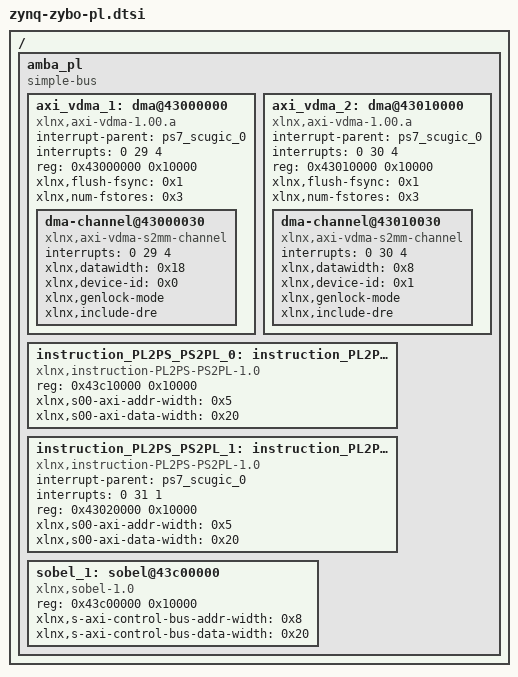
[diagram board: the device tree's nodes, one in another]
/*
 * CAUTION: This file is automatically generated by Xilinx.
 * Version: HSI 
 * Today is: Thu Jan 14 14:43:05 2016
*/


/  {
	amba_pl: amba_pl {
		#address-cells = <1>;
		#size-cells = <1>;
		compatible = "simple-bus";
		ranges ;
		axi_vdma_1: dma@43000000 {
			#dma-cells = <1>;
			compatible = "xlnx,axi-vdma-1.00.a";
			interrupt-parent = <&ps7_scugic_0>;
			interrupts = <0 29 4>;
			reg = <0x43000000 0x10000>;
			xlnx,flush-fsync = <0x1>;
			xlnx,num-fstores = <0x3>;
			dma-channel@43000030 {
				compatible = "xlnx,axi-vdma-s2mm-channel";
				interrupts = <0 29 4>;
				xlnx,datawidth = <0x18>;
				xlnx,device-id = <0x0>;
				xlnx,genlock-mode ;
				xlnx,include-dre ;
			};
		};
		axi_vdma_2: dma@43010000 {
			#dma-cells = <1>;
			compatible = "xlnx,axi-vdma-1.00.a";
			interrupt-parent = <&ps7_scugic_0>;
			interrupts = <0 30 4>;
			reg = <0x43010000 0x10000>;
			xlnx,flush-fsync = <0x1>;
			xlnx,num-fstores = <0x3>;
			dma-channel@43010030 {
				compatible = "xlnx,axi-vdma-s2mm-channel";
				interrupts = <0 30 4>;
				xlnx,datawidth = <0x8>;
				xlnx,device-id = <0x1>;
				xlnx,genlock-mode ;
				xlnx,include-dre ;
			};
		};
		instruction_PL2PS_PS2PL_0: instruction_PL2PS_PS2PL@43c10000 {
			compatible = "xlnx,instruction-PL2PS-PS2PL-1.0";
			reg = <0x43c10000 0x10000>;
			xlnx,s00-axi-addr-width = <0x5>;
			xlnx,s00-axi-data-width = <0x20>;
		};
		instruction_PL2PS_PS2PL_1: instruction_PL2PS_PS2PL@43020000 {
			compatible = "xlnx,instruction-PL2PS-PS2PL-1.0";
	                interrupt-parent = <&ps7_scugic_0>;
			interrupts = <0 31 1>;
			reg = <0x43020000 0x10000>;
			xlnx,s00-axi-addr-width = <0x5>;
			xlnx,s00-axi-data-width = <0x20>;
		};
		sobel_1: sobel@43c00000 {
			compatible = "xlnx,sobel-1.0";
			reg = <0x43c00000 0x10000>;
			xlnx,s-axi-control-bus-addr-width = <0x8>;
			xlnx,s-axi-control-bus-data-width = <0x20>;
		};
	};
};
